# H6 register map
Vendor: Allwinner; Series: H6; File version: 0.1
CPU: CA53 0, little endian, MPU, no FPU, 0 interrupt priority bits
Registers are 32-bit, read-write, reset 0x0 unless marked. A register's access mark holds for its fields unless they carry their own. Offsets are from the block's base; [hi:lo] are bit positions; {n}, {i} and the like mark numbered series; 'fields as' and 'values as' point back to an identical list.

## IOMMU
Base 0x030F0000
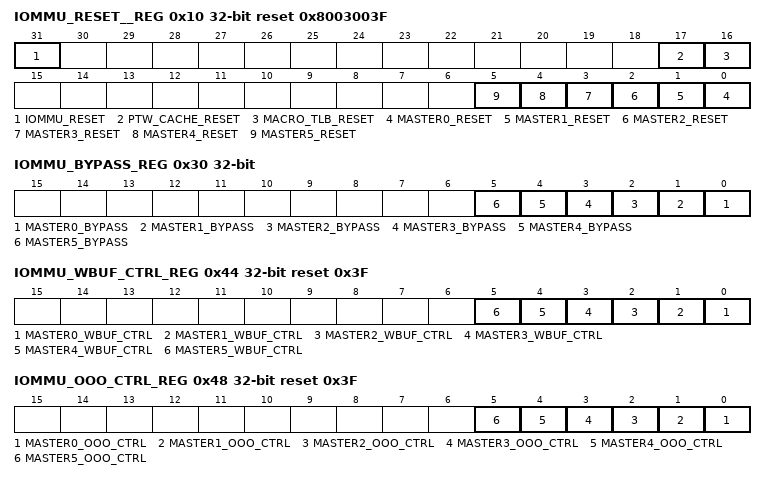
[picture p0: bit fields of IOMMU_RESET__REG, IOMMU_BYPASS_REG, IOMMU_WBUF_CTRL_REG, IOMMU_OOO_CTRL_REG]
0x10 IOMMU_RESET__REG reset 0x8003003F
  [31] IOMMU_RESET — IOMMU Software Reset Switch 0: Set reset signal 1: Release reset signal Before IOMMU software reset operation, ensure IOMMU never be opened; Or no unfinished bus operation; Or DRAM and the peripherals have opened the corresponding switch, for shielding the effects of IOMMU reset .
    0=Set (Set reset signal); 1=Release reset signal Before IOMMU software reset operation, ensure IOMMU never be opened; Or no unfinished bus operation; Or DRAM and the peripherals have opened the corresponding switch, for shielding the effects of IOMMU reset 
  [17] PTW_CACHE_RESET — PTW Cache address convert lane software reset switch. 0: Set reset signal 1: Release reset signal When PTW Cache occurs abnormal, the bit is used for resetting PTW Cache individually.
    0=Set (Set reset signal); 1=Release reset signal When PTW Cache occurs abnormal, the bit is used for resetting PTW Cache individually
  [16] MACRO_TLB_RESET — Macro TLB address convert lane software reset switch. 0: Set reset signal 1: Release reset signal When PTW Cache occurs abnormal, the bit is used for resetting PTW Cache individually.
    values as PTW_CACHE_RESET
  [n] MASTER{n}_RESET (n=0..5) — Master{n} address convert lane software reset switch. 0: Set reset signal 1: Release reset signal When Master{n} occurs abnormal, the bit is used for resetting PTW Cache individually.
    0=Set (Set reset signal); 1=Release reset signal When Master{n} occurs abnormal, the bit is used for resetting PTW Cache individually
0x20 IOMMU_ENABLE_REG — IOMMU Enable Register
  [0] ENABLE — IOMMU module enable switch 0: Disable IOMMU 1: Enable IOMMU Before IOMMU address mapping function opens, configure the Translation Table Base register; or ensure all masters are in bypass status or no the status of sending bus demand such as reset
    0=Disable IOMMU; 1=Enable IOMMU Before IOMMU address mapping function opens, configure the Translation Table Base register; or ensure all masters are in bypass status or no the status of sending bus demand such as reset
0x30 IOMMU_BYPASS_REG — IOMMU Bypass Register
  [all] fields
    0=Disable bypass function; 1=Enable bypass function
  [n] MASTER{n}_BYPASS (n=0..5) — Master{n} bypass switch After open bypass function IOMMU can not map the address of Master{n} sending, and directly output the virtual address to MBUS as physical address. 0: Disable bypass function 1: Enable bypass function
0x40 IOMMU_AUTO_GATING_REG — IOMMU Auto Gating Register
  [0] IOMMU_AUTO_GATING — IOMMU circuit auto gating control. The purpose is decreasing power consumption of the module. 0: Disable auto gating function 1: Enable auto gating function
    0=Disable auto gating function; 1=Enable auto gating function
0x44 IOMMU_WBUF_CTRL_REG reset 0x3F — IOMMU Write Buffer Control Register
  [all] fields
    0=Disable write buffer; 1=Enable write buffer
  [n] MASTER{n}_WBUF_CTRL (n=0..5) — Master{n} write buffer control bit 0: Disable write buffer 1: Enable write buffer
0x48 IOMMU_OOO_CTRL_REG reset 0x3F — IOMMU Out Of Order Control Register
  [all] fields
    0=Disable out-of-order; 1=Enable out-of-order
  [n] MASTER{n}_OOO_CTRL (n=0..5) — Master{n} out-of-order control bit 0: Disable out-of-order 1: Enable out-of-order
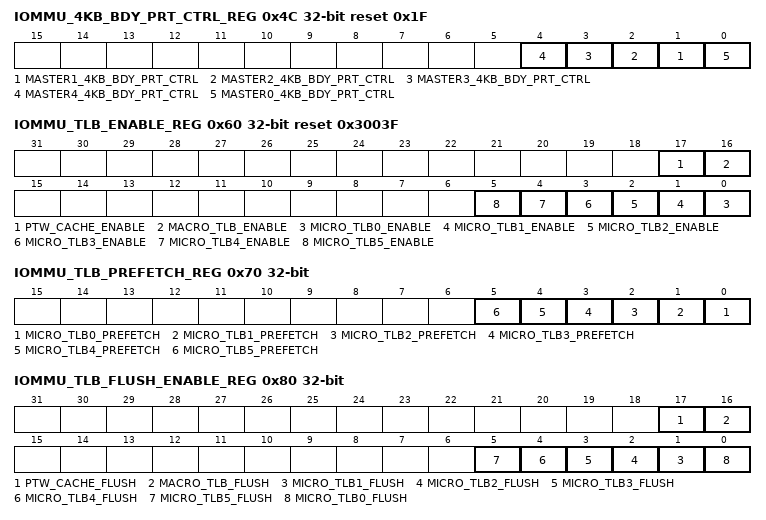
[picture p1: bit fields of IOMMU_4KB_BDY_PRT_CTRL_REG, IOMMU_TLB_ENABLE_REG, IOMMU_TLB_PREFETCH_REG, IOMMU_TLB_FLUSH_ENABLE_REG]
0x4C IOMMU_4KB_BDY_PRT_CTRL_REG reset 0x1F — IOMMU 4KB Boundary Protect Control Register
  [n] MASTER{n}_4KB_BDY_PRT_CTRL (n=1..4) — Master{n} 4KB boundary protect control bit 0: Disable 4KB boundary protect 1: Enable 4KB boundary protect
    0=Disable 4KB boundary protect; 1=Enable 4KB boundary protect
  [0] MASTER0_4KB_BDY_PRT_CTRL — Master0 4KB boundary protect control bit 0: Disable 4KB boundary protect 1: Enable 4KB boundary protect NOTE When Master sends the burst of over 4KB boundary, IOMMU can split demand and data.
    0=Disable 4KB boundary protect; 1=Enable 4KB boundary protect NOTE When Master sends the burst of over 4KB boundary, IOMMU can split demand and data
0x50 IOMMU_TTB_REG — IOMMU Translation Table Base Register
  [31:14] TTB — Level1 page table starting address, aligned to 16 KB. NOTE When operating the register , IOMMU address mapping function must be closed, namely IOMMU_ENABLE_REG is 0 ; Or Bypass function of all main equipment is set to 1 or not the state of transfer bus commands (such as setting).
0x60 IOMMU_TLB_ENABLE_REG reset 0x3003F — IOMMU TLB Enable Register
  [all] fields
    0=Disable; 1=Enable
  [17] PTW_CACHE_ENABLE — PTW Cache enable bit 0: Disable 1: Enable
  [16] MACRO_TLB_ENABLE — Macro TLB enable bit 0: Disable 1: Enable
  [n] MICRO_TLB{n}_ENABLE (n=0..5) — Micro TLB{n} enable bit 0: Disable 1: Enable
0x70 IOMMU_TLB_PREFETCH_REG — IOMMU TLB Prefetch Register
  [all] fields
    0=Disable; 1=Enable
  [n] MICRO_TLB{n}_PREFETCH (n=0..5) — Micro TLB{n} prefetch enable 0: Disable 1: Enable
0x80 IOMMU_TLB_FLUSH_ENABLE_REG — IOMMU TLB Flush Enable Register
  [all] fields
    0=No clear operation or clear operation completed; 1=Enable is cleared After Flush operation completes, the bit can clear 0 automatically
  [17] PTW_CACHE_FLUSH — Clear PTW Cache 0: No clear operation or clear operation completed 1: Enable is cleared After Flush operation completes, the bit can clear 0 automatically.
  [16] MACRO_TLB_FLUSH — Clear Macro TLB 0: No clear operation or clear operation completed 1: Enable is cleared After Flush operation completes, the bit can clear 0 automatically.
  [n] MICRO_TLB{n}_FLUSH (n=1..5) — Clear Micro TLB{n} 0: No clear operation or clear operation completed 1: Enable is cleared After Flush operation completes, the bit can clear 0 automatically.
  [0] MICRO_TLB0_FLUSH — Clear Micro TLB1 0: No clear operation or clear operation completed 1: Enable is cleared After Flush operation completes, the bit can clear 0 automatically.
0x90 IOMMU_TLB_IVLD_ADDR_REG — IOMMU TLB Invalidation Address Register
  [31:12] TLB_IVLD_ADDR — TLB invalid address, aligned to 4K
0x94 IOMMU_TLB_IVLD_ADDR_MASK_REG — IOMMU TLB Invalidation Address Mask Register
  [31:12] TLB_IVLD_ADDR_MASK — TLB invalid address mask register, aligned to 4K
0x98 IOMMU_TLB_IVLD_ENABLE_REG — IOMMU TLB Invalidation Enable Register
  [0] TLB_IVLD_ENABLE — Enable TLB invalid operation 0: No-operation or operation completed 1: Enable is invalid After invalidation operation completed, the bit can clear 0 automatically. When operating Invalidation, TLB/Cache operation has not affected. After or Before Invalidation starts, t here is no absolute relationship between same address switch operation and Invalidation operation.
    0=No-operation or operation completed; 1=Enable is invalid After invalidation operation completed, the bit can clear 0 automatically. When operating Invalidation, TLB/Cache operation has not affected. After or Before Invalidation starts, t here is no absolute relationship between same address switch operation and Invalidation operation.
0xA0 IOMMU_PC_IVLD_ADDR_REG — IOMMU PC Invalidation Address Register
  [31:20] PC_IVLD_ADDR — PTW Cache invalid address, aligned to 1M.
0xA8 IOMMU_PC_IVLD_ENABLE_REG — IOMMU PC Invalidation Enable Register
  [0] PC_IVLD_ENABLE — Enable PTW Cache invalid operation 0: No-operation or operation completed 1: Enable is invalid After invalidation operation completed, the bit can clear 0 automatically. After or Before Invalidation starts, t here is no absolute relationship between same address switch operation and Invalidation operation.
    0=No-operation or operation completed; 1=Enable is invalid After invalidation operation completed, the bit can clear 0 automatically. After or Before Invalidation starts, t here is no absolute relationship between same address switch operation and Invalidation operation.
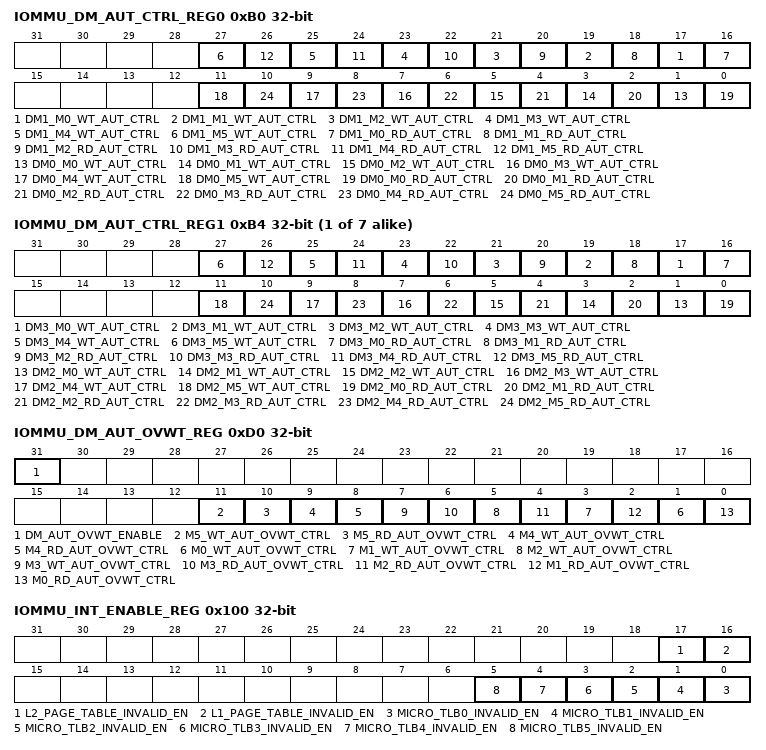
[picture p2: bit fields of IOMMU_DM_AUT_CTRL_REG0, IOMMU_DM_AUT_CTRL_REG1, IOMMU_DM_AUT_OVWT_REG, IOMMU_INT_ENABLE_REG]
0xB0 IOMMU_DM_AUT_CTRL_REG0 — IOMMU Domain Authority Control Register 0
  [2n+17] DM1_M{n}_WT_AUT_CTRL (n=0..5) — Domain1 write permission control for master{n} 0: The write-operation is available 1: The write-operation is unavailable
    0=available (The write-operation is available); 1=unavailable (The write-operation is unavailable)
  [2n+16] DM1_M{n}_RD_AUT_CTRL (n=0..5) — Domain1 read permission control for master{n} 0: The read-operation is available 1: The read-operation is unavailable
    0=available (The read-operation is available); 1=unavailable (The read-operation is unavailable)
  [2n+1] DM0_M{n}_WT_AUT_CTRL ro (n=0..5) — Domain0 write permission control for master{n} 0: The write-operation is available 1: The write-operation is unavailable
    values as DM1_M0_WT_AUT_CTRL
  [2n] DM0_M{n}_RD_AUT_CTRL ro (n=0..5) — Domain0 read permission control for master{n} 0: The read-operation is available 1: The read-operation is unavailable
    values as DM1_M0_RD_AUT_CTRL
{0xB0+4i} IOMMU_DM_AUT_CTRL_REG{i} (i=1..7) — IOMMU Domain Authority Control Register {i}
  [2n+17] DM{2i+1}_M{n}_WT_AUT_CTRL (n=0..5) — Domain{2i+1} write permission control for master{n} 0: The write-operation is available 1: The write-operation is unavailable
    values as IOMMU_DM_AUT_CTRL_REG0.DM1_M0_WT_AUT_CTRL
  [2n+16] DM{2i+1}_M{n}_RD_AUT_CTRL (n=0..5) — Domain{2i+1} read permission control for master{n} 0: The read-operation is available 1: The read-operation is unavailable
    values as IOMMU_DM_AUT_CTRL_REG0.DM1_M0_RD_AUT_CTRL
  [2n+1] DM{2i}_M{n}_WT_AUT_CTRL (n=0..5) — Domain{2i} write permission control for master{n} 0: The write-operation is available 1: The write-operation is unavailable
    values as IOMMU_DM_AUT_CTRL_REG0.DM1_M0_WT_AUT_CTRL
  [2n] DM{2i}_M{n}_RD_AUT_CTRL (n=0..5) — Domain{2i} read permission control for master{n} 0: The read-operation is available 1: The read-operation is unavailable
    values as IOMMU_DM_AUT_CTRL_REG0.DM1_M0_RD_AUT_CTRL
0xD0 IOMMU_DM_AUT_OVWT_REG — IOMMU Domain Authority Overwrite Register
  [31] DM_AUT_OVWT_ENABLE — Domain write/read permission overwrite enable 0: Disable 1: Enable
    0=Disable; 1=Enable
  [11] M5_WT_AUT_OVWT_CTRL — Master5 write permission overwrite control 0: The write-operation is available 1: The write-operation is unavailable
    values as IOMMU_DM_AUT_CTRL_REG0.DM1_M0_WT_AUT_CTRL
  [10] M5_RD_AUT_OVWT_CTRL — Master5 read permission overwrite control 0: The read-operation is available 1: The read-operation is unavailable
    values as IOMMU_DM_AUT_CTRL_REG0.DM1_M0_RD_AUT_CTRL
  [9] M4_WT_AUT_OVWT_CTRL — Master5 write permission overwrite control 0: The write-operation is available 1: The write-operation is unavailable
    values as IOMMU_DM_AUT_CTRL_REG0.DM1_M0_WT_AUT_CTRL
  [8] M4_RD_AUT_OVWT_CTRL — Master5 read permission overwrite control 0: The read-operation is available 1: The read-operation is unavailable
    values as IOMMU_DM_AUT_CTRL_REG0.DM1_M0_RD_AUT_CTRL
  [2n+1] M{n}_WT_AUT_OVWT_CTRL (n=0..3) — Master{n} write permission overwrite control 0: The write-operation is available 1: The write-operation is unavailable
    values as IOMMU_DM_AUT_CTRL_REG0.DM1_M0_WT_AUT_CTRL
  [6] M3_RD_AUT_OVWT_CTRL — Master3 read permission overwrite control 0: The read-operation is available 1: The read-operation is unavailable
    values as IOMMU_DM_AUT_CTRL_REG0.DM1_M0_RD_AUT_CTRL
  [4] M2_RD_AUT_OVWT_CTRL — Master2 read permission overwrite control 0: The read-operation is available 1: The read-operation is unavailable
    values as IOMMU_DM_AUT_CTRL_REG0.DM1_M0_RD_AUT_CTRL
  [2] M1_RD_AUT_OVWT_CTRL — Master1 read permission overwrite control 0: The read-operation is available 1: The read-operation is unavailable
    values as IOMMU_DM_AUT_CTRL_REG0.DM1_M0_RD_AUT_CTRL
  [0] M0_RD_AUT_OVWT_CTRL — Master0 read permission overwrite control 0: The read-operation is available 1: The read-operation is unavailable REG_ARD_OVWT IOMMU_DM_AUT_CTRL_REG0~7 Domain REG_ARD_OVWT
    0=available (The read-operation is available); 1=unavailable (The read-operation is unavailable REG_ARD_OVWT IOMMU_DM_AUT_CTRL_REG0~7 Domain REG_ARD_OVWT)
0x100 IOMMU_INT_ENABLE_REG
  [all] fields
    0=Mask interrupt; 1=Enable interrupt
  [17] L2_PAGE_TABLE_INVALID_EN — Level2 page table invalid interrupt enable 0: Mask interrupt 1: Enable interrupt
  [16] L1_PAGE_TABLE_INVALID_EN — Level1 page table invalid interrupt enable 0: Mask interrupt 1: Enable interrupt
  [n] MICRO_TLB{n}_INVALID_EN (n=0..5) — Micro TLB{n} permission invalid interrupt enable 0: Mask interrupt 1: Enable interrupt
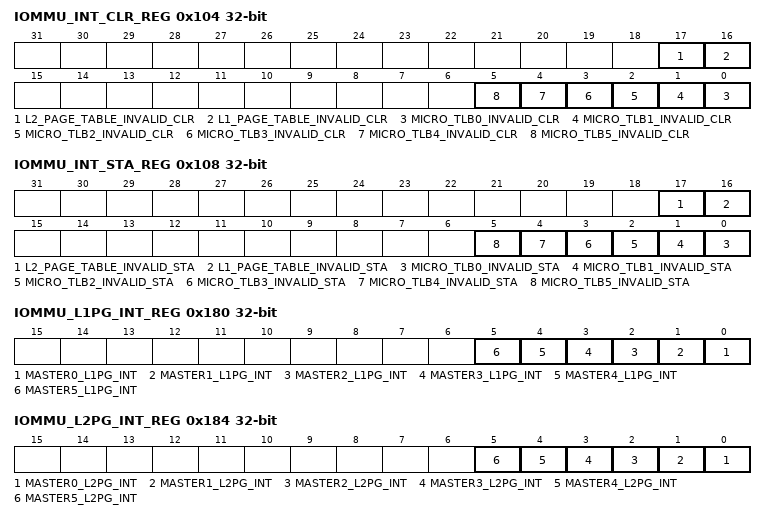
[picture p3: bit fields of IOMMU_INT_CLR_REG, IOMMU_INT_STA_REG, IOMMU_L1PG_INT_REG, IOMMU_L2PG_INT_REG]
0x104 IOMMU_INT_CLR_REG
  [all] fields
    0=Invalid operation; 1=Clear interrupt
  [17] L2_PAGE_TABLE_INVALID_CLR wo — Level2 page table invalid interrupt clear bit 0: Invalid operation 1: Clear interrupt
  [16] L1_PAGE_TABLE_INVALID_CLR wo — Level1 page table invalid interrupt clear bit 0: Invalid operation 1: Clear interrupt
  [n] MICRO_TLB{n}_INVALID_CLR wo (n=0..5) — Micro TLB{n} permission invalid interrupt clear bit 0: Invalid operation 1: Clear interrupt
0x108 IOMMU_INT_STA_REG
  [all] fields
    0=Interrupt does not happen or interrupt is cleared; 1=Interrupt_happens
  [17] L2_PAGE_TABLE_INVALID_STA ro — Level2 page table invalid interrupt status bit 0: Interrupt does not happen or interrupt is cleared 1: Interrupt happens
  [16] L1_PAGE_TABLE_INVALID_STA ro — Level2 page table invalid interrupt status bit 0: Interrupt does not happen or interrupt is cleared 1: Interrupt happens
  [n] MICRO_TLB{n}_INVALID_STA ro (n=0..5) — Micro TLB{n} permission invalid interrupt status bit 0: Interrupt does not happen or interrupt is cleared 1: Interrupt happens
{0x110+4i} IOMMU_INT_ERR_ADDR_REG{i} (i=0..5) — IOMMU Interrupt Error Address Register {i}
  [31:0] INT_ERR_ADDR{i} ro — Virtual address causing Micro TLB{i} occurs interrupt
0x130 IOMMU_INT_ERR_ADDR_REG6 — IOMMU Interrupt Error Address Register 6
  [31:0] INT_ERR_ADDR6 ro — Virtual address causing Micro TLB6 occurs interrupt
0x134 IOMMU_INT_ERR_ADDR_REG7 — IOMMU Interrupt Error Address Register 7
  [31:0] INT_ERR_ADDR7 ro — Virtual address causing Micro TLB7 occurs interrupt
{0x150+4i} IOMMU_INT_ERR_DATA_REG{i} (i=0..5) — IOMMU Interrupt Error Data Register {i}
  [31:0] INT_ERR_DATA{i} ro — Corresponding page table of virtual address causing Micro TLB{i} occurs interrupt
0x170 IOMMU_INT_ERR_DATA_REG6 — IOMMU Interrupt Error Data Register 6
  [31:0] INT_ERR_DATA6 ro — Corresponding page table of virtual address causing Micro TLB6 occurs interrupt
0x174 IOMMU_INT_ERR_DATA_REG7 — IOMMU Interrupt Error Data Register 7
  [31:0] INT_ERR_DATA7 ro — Corresponding page table of virtual address causing Micro TLB7 occurs interrupt
0x180 IOMMU_L1PG_INT_REG
  [n] MASTER{n}_L1PG_INT ro (n=0..5) — Master{n} address switch causes L1 page table to occur interrupt.
0x184 IOMMU_L2PG_INT_REG
  [n] MASTER{n}_L2PG_INT ro (n=0..5) — Master{n} address switch causes L2 page table to occur interrupt.
0x190 IOMMU_VA__REG
  [31:0] VA — Virtual address of read/write
0x194 IOMMU_VA_DATA__REG
  [31:0] VA_DATA — Data of read/write virtual address
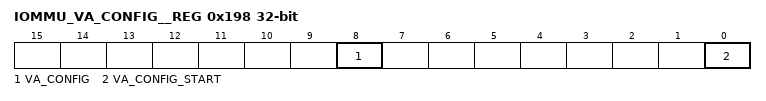
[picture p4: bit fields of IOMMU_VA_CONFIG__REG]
0x198 IOMMU_VA_CONFIG__REG
  [8] VA_CONFIG — 0: Read operation 1: Write operation
    0=Read operation; 1=Write operation
  [0] VA_CONFIG_START — 0: No operation or operation completes 1: Start After the operation completes, the bit can clear to 0 automatically.
    0=No operation or operation completes; 1=Start After the operation completes, the bit can clear to 0 automatically
0x200 IOMMU_PMU_ENABLE__REG
  [0] PMU_ENABLE — 0: Disable statistical function 1: Enable statistical function
    0=Disable statistical function; 1=Enable statistical function
0x210 IOMMU_PMU_CLR__REG
  [0] PMU_CLR — 0: No clear operation or clear operation completes 1: Clear counter data After the operation completes, the bit can clear to 0 automatically.
    0=No clear operation or clear operation completes; 1=Clear counter data After the operation completes, the bit can clear to 0 automatically
{0x230+0x10*i} IOMMU_PMU_ACCESS_LOW_REG{i} (i=0..2) — IOMMU PMU Access Low Register {i}
  [31:0] PMU_ACCESS_LOW{i} ro — Record total number of Micro TLB{i} access , lower 32-bit register
{0x234+0x10*i} IOMMU_PMU_ACCESS_HIGH_REG{i} (i=0..3) — IOMMU PMU Access High Register {i}
  [10:0] PMU_ACCESS_HIGH{i} ro — Record total number of Micro TLB{i} access , higher 11-bit register
{0x238+0x10*i} IOMMU_PMU_HIT_LOW_REG{i} (i=0..2) — IOMMU PMU Hit Low Register {i}
  [31:0] PMU_HIT_LOW{i} ro — Record total number of Micro TLB{i} hit , lower 32-bit register
{0x23C+0x10*i} IOMMU_PMU_HIT_HIGH_REG{i} (i=0..3) — IOMMU PMU Hit High Register {i}
  [10:0] PMU_HIT_HIGH{i} ro — Record total number of Micro TLB{i} hit , higher 11-bit register
{0x230+0x10*i} IOMMU_PMU_ACCESS_LOW_REG{i} (i=3..5) — IOMMU PMU Access Low Register {i}
  [31:0] PMU_ACCESS_LOW{i} ro — Record total number of Micro TLB{i} access, lower 32-bit register
{0x238+0x10*i} IOMMU_PMU_HIT_LOW_REG{i} (i=3..5) — IOMMU PMU Hit Low Register {i}
  [31:0] PMU_HIT_LOW{i} ro — Record total number of Micro TLB{i} hit, lower 32-bit register
0x274 IOMMU_PMU_ACCESS_HIGH_REG4 — IOMMU PMU Access High Register 4
  [10:0] PMU_ACCESS_HIGH4 ro — Record total number of Micro TLB4 access, higher 11-bit register
0x27C IOMMU_PMU_HIT_HIGH_REG4 — IOMMU PMU Hit High Register 4
  [10:0] PMU_HIT_HIGH4 ro — Record total number of Micro TLB4 hit, higher 11-bit register
0x284 IOMMU_PMU_ACCESS_HIGH_REG5 — IOMMU PMU Access High Register 5
  [10:0] PMU_ACCESS_HIGH5 ro — Record total number of Micro TLB5 access, higher 11-bit register
0x28C IOMMU_PMU_HIT_HIGH_REG5 — IOMMU PMU Hit High Register 5
  [10:0] PMU_HIT_HIGH5 ro — Record total number of Micro TLB5 hit, higher 11-bit register
0x2D0 IOMMU_PMU_ACCESS_LOW_REG6 — IOMMU PMU Access Low Register 6
  [31:0] PMU_ACCESS_LOW6 ro — Record total number of Micro TLB6 access, lower 32-bit register
0x2D4 IOMMU_PMU_ACCESS_HIGH_REG6 — IOMMU PMU Access High Register 6
  [10:0] PMU_ACCESS_HIGH6 ro — Record total number of Micro TLB6 access, higher 11-bit register
0x2D8 IOMMU_PMU_HIT_LOW_REG6 — IOMMU PMU Hit Low Register 6
  [31:0] PMU_HIT_LOW6 ro — Record total number of Micro TLB6 hit, lower 32-bit register
0x2DC IOMMU_PMU_HIT_HIGH_REG6 — IOMMU PMU Hit High Register 6
  [10:0] PMU_HIT_HIGH6 ro — Record total number of Micro TLB6 hit, higher 11-bit register
0x2E0 IOMMU_PMU_ACCESS_LOW_REG7 — IOMMU PMU Access Low Register 7
  [31:0] PMU_ACCESS_LOW7 ro — Record total number of PTW Cache access, lower 32-bit register
0x2E4 IOMMU_PMU_ACCESS_HIGH_REG7 — IOMMU PMU Access High Register 7
  [10:0] PMU_ACCESS_HIGH7 ro — Record total number of PTW Cache access, higher 11-bit register
0x2E8 IOMMU_PMU_HIT_LOW_REG7 — IOMMU PMU Hit Low Register 7
  [31:0] PMU_HIT_LOW7 ro — Record total number of PTW Cache hit, lower 32-bit register
0x2EC IOMMU_PMU_HIT_HIGH_REG7 — IOMMU PMU Hit High Register 7
  [10:0] PMU_HIT_HIGH7 ro — Record total number of PTW Cache hit, higher 11-bit register
{0x300+0x10*i} IOMMU_PMU_TL_LOW_REG{i} (i=0..5)
  [31:0] PMU_TL_LOW{i} ro — Record total latency of Master{i}, lower 32-bit register
{0x304+0x10*i} IOMMU_PMU_TL_HIGH_REG{i} (i=0..5)
  [17:0] PMU_TL_HIGH{i} ro — Record total latency of Master{i}, higher 18-bit register
